# ET6801 register map
Vendor: ETMCU Inc.; File version: v0.0.1
CPU: CM7 r2p1, little endian, MPU, FPU, I-cache, D-cache, ITCM, DTCM, 4 interrupt priority bits
Registers are 32-bit, read-write, reset 0x0 unless marked. A register's access mark holds for its fields unless they carry their own. Offsets are from the block's base; [hi:lo] are bit positions; lines under a group give offsets from that group; {n}, {i} and the like mark numbered series.

## SDFM0 — Provide an overview of the purpose and functionality of the peripheral: sdfm_cfg
Base 0x40115000
Same registers: SDFM1 0x40116000, SDFM2 0x40117000, SDFM3 0x40118000
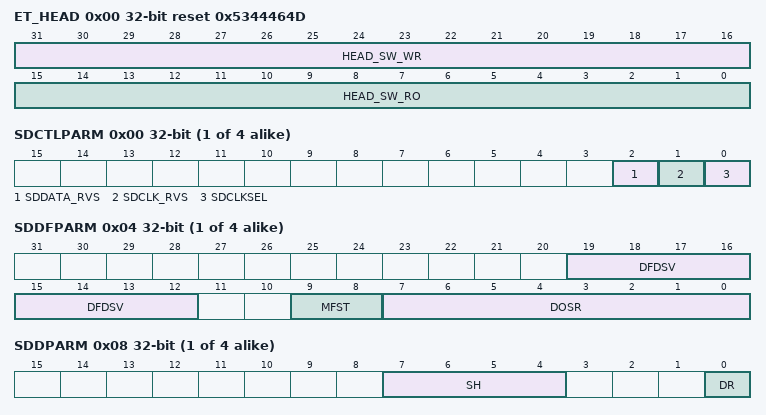
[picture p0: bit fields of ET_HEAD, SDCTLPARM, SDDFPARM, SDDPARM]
0x00 ET_HEAD reset 0x5344464D
  [31:16] HEAD_SW_WR — 软件测试读写寄存器，硬件无访问，静态寄存器
  [15:0] HEAD_SW_RO ro — 软件只读上报寄存器，硬件无访问,SDFM的ASICII 码表示，静态寄存器
{0x4+0x48*i} SDCHNX_GRP[{i}] (i=0..3) group
  0x00 SDCTLPARM
    [2] SDDATA_RVS — SD输入数据信号反向
    [1] SDCLK_RVS — SD输入时钟反向
    [0] SDCLKSEL — SD时钟源选择 对于通道1，当有多个SDFM模块挂到总线上时，是否选择其他SDFM模块通道1的滤波器时钟源为当前SDFM模块通道1的滤波器时钟源 'd0:通道1的滤波器的时钟源为自己通道的时钟； 'd1:通道1的滤波器的时钟源为其他SDFM模块的通道1的滤波器的时钟源 对于通道2~4 'd0:到SDFM滤波器的时钟源为自己通道的时钟源； 'd1:到SDFM滤波器的时钟源为当前SDFM模块通道1滤波器时钟源；
  0x04 SDDFPARM
    [19:12] DFDSV — 数据滤波器抽取计数器起始值(Data Filter Decimation count Start Value)，当开始或重新启动时，抽取计数器从值cfg_dfdsv开始计数。有效值为0~dosr。
    [9:8] MFST — 数据滤波器结构 'd0:数据过滤器以Sincfast结构运行; 'd1:数据过滤器以Sinc1结构运行; 'd2:数据过滤器以Sinc2结构运行; 'd3:数据过滤器以Sinc3结构运行;
    [7:0] DOSR — 数据滤波器过采样率 数据滤波器的实际过采样率为DOSR + 1。这些位设置了数据滤波器的过采样率。例如:0x0FF表示过采样率为256。
  0x08 SDDPARM
    [7:4] SH — 移位控制 这些位表示当选择16位数据表示时，16位窗口向上移动了多少位。
    [0] DR — 数据滤波器数据表示 'd0:以16位二进制补码存储数据； 'd1:以32位二进制补码存储数据；
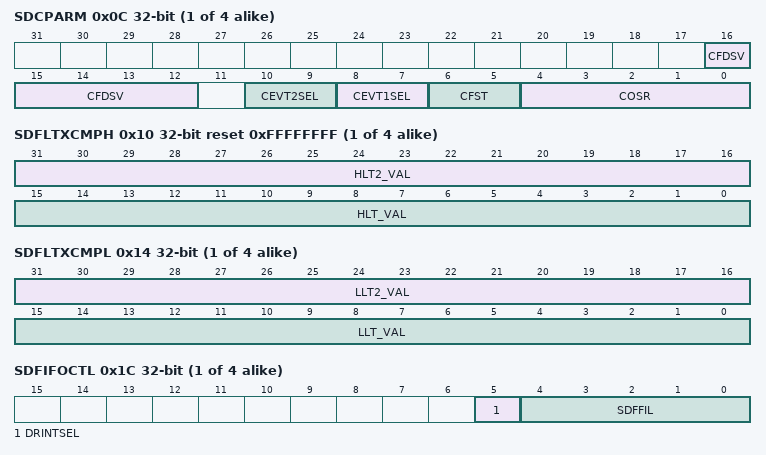
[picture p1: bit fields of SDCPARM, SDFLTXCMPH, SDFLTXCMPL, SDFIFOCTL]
  0x0C SDCPARM
    [16:12] CFDSV — 比较滤波器抽取计数器起始值(Comparator Filter Decimation count Start Value)，当开始或重新启动时，抽取计数器从值cfg_cfdsv开始计数。有效值为0~cosr。
    [10:9] CEVT2SEL — 比较器event2选择 'd0:compl1； 'd1: compl1或者comph1； 'd2:compl2； 'd3: compl2或者comph2；
    [8:7] CEVT1SEL — 比较器event1选择 'd0:comph1； 'd1: compl1或者comph1； 'd2:comph2； 'd3: compl2或者comph2；
    [6:5] CFST — 比较器滤波器结构 'd0:比较滤波器以sincfast结构运行 'd1:比较滤波器以Sinc1结构运行 'd2:比较滤波器以Sinc2结构运行 'd3:比较滤波器以Sinc3结构运行
    [4:0] COSR — 比较器过采样率 实际过采样率位COSR + 1，这些位设置了滤波器的过采样率。例如：0x1F表示过采样比为32
  0x10 SDFLTXCMPH reset 0xFFFFFFFF
    [31:16] HLT2_VAL — 比较滤波器输出的第二个无符号高阈值；
    [15:0] HLT_VAL — 比较滤波器输出的无符号高阈值。
  0x14 SDFLTXCMPL
    [31:16] LLT2_VAL — 比较滤波器输出的第二个无符号低阈值。
    [15:0] LLT_VAL — 比较滤波器输出的无符号低阈值。
  0x18 SDFLTXCMPHZ
    [15:0] HLTZ_VAL — 比较滤波器输出的无符号高阈值(Z)主要用于检测"零"交叉事件。与主比较器SDCMPHx不同，它不具有生成中断的能力。
  0x1C SDFIFOCTL
    [5] DRINTSEL — 数据就绪中断(DRINT)源选择 'd0: AFx(选择非fifo数据就绪中断) 'd1:SDFFINTx(选择FIFO数据就绪中断)
    [4:0] SDFFIL — SDFIFO中断门限 当FIFO状态(SDFFST) >= FIFO门限(SDFFIL)时，FIFO将产生中断。
  0x20 SDSYNC
    [5:0] SYNCSEL — 定义此通道上的SDSYNC输入源，0~35分别对应pwm输入信号的0~35输入源；其余选择为输入为0
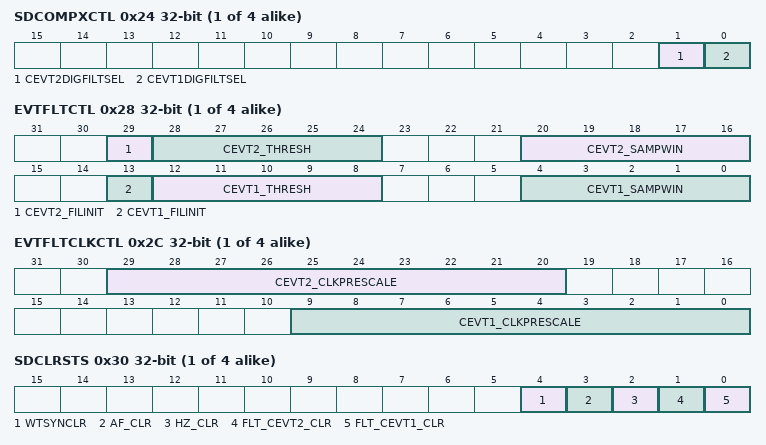
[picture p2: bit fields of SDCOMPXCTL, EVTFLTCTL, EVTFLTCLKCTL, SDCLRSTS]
  0x24 SDCOMPXCTL
    [1] CEVT2DIGFILTSEL — cevt2事件源选择。 'd0:CEVT2输出驱动器cevt2事件 'd1:数字滤波器输出驱动cevt2事件
    [0] CEVT1DIGFILTSEL — cevt1事件源选择。 'd0:CEVT1输出驱动器cevt1事件 'd1:数字滤波器输出驱动cevt1事件
  0x28 EVTFLTCTL
    [29] CEVT2_FILINIT wo — cevt2滤波器初始化。 'd0:无影响 'd1:将所有样本初始化为滤波器输入值
    [28:24] CEVT2_THRESH — cevt2滤波器多数投票阈值。为了使输出改变状态，必须在样本窗口内出现至少（THRESH+1）个相反状态的样本。
    [20:16] CEVT2_SAMPWIN — cevt2滤波器样本窗口大小。要监控的采样数为SAMPWIN+1。
    [13] CEVT1_FILINIT wo — cevt1滤波器初始化。 'd0:无影响 'd1:将所有样本初始化为滤波器输入值
    [12:8] CEVT1_THRESH — cevt1滤波器多数投票阈值。为了使输出改变状态，必须在样本窗口内出现至少（THRESH+1）个相反状态的样本。
    [4:0] CEVT1_SAMPWIN — cevt1滤波器样本窗口大小。要监控的采样数为SAMPWIN+1。
  0x2C EVTFLTCLKCTL
    [29:20] CEVT2_CLKPRESCALE — cevt2滤波器采样时钟预刻度。采样之间的系统时钟数。
    [9:0] CEVT1_CLKPRESCALE — cevt1滤波器采样时钟预刻度。采样之间的系统时钟数。
  0x30 SDCLRSTS
    [4] WTSYNCLR — 动态寄存器 Wait-for-Sync Flag Clear 'd0:写0不影响； 'd1:写1清空WTSYNFLG； 注：wtsynflg_rpt为fifo使用pwm同步功能时的fifo enable实时上报信号，如果用此处用硬件自清0，软件很有可能看不到wtsynflg_rpt清零的状态；
    [3] AF_CLR — 动态寄存器 主滤波器应答标志清除位
    [2] HZ_CLR — 动态寄存器 hz_rpt标志清除位
    [1] FLT_CEVT2_CLR — 动态寄存器 比较滤波器的CEVT2标志清除位
    [0] FLT_CEVT1_CLR — 动态寄存器 比较滤波器的CEVT1标志清除位
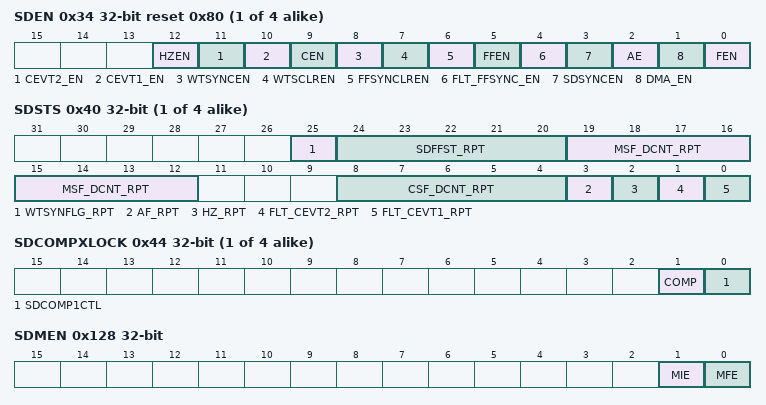
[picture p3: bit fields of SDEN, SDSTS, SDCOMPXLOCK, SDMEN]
  0x34 SDEN reset 0x80
    [12] HZEN — 动态寄存器 高电平(Z)使能阈值交叉输出 'd0:关闭高电平阈值(Z)交叉； 'd1:使能高电平阈值(Z)交叉；
    [11] CEVT2_EN — 动态寄存器 使能cevt2 'd0:关闭cevt2 'd1:使能cevt2
    [10] CEVT1_EN — 动态寄存器 使能cevt1 'd0:关闭cevt1 'd1:使能cevt1
    [9] CEN — 动态寄存器 比较滤波器使能 'd0:失能比较滤波器； 'd1:使能比较滤波器；
    [8] WTSYNCEN — 动态寄存器 Wait-for-Sync使能 'd0:每次DR (Data- ready)事件时，输入数据写入SDFIFO； 'd1:在发生SDSYNC事件后，DR事件的输入数据才会写入SDFIFO；
    [7] WTSCLREN — 动态寄存器 WTSYNFLG Clear-on-FIFOINT Enable 'd0: WTSYNFLG只能手动清除(使用WTSYNCLR位) 'd1:在SDFFINT有效时自动清除WTSYNFLG
    [6] FFSYNCLREN — 动态寄存器 FIFO Clear-on-SDSYNC Enable 'd0:表示SDFIFO接收到SDSYNC后不自动清除 'd1:SDFIFO接收到SDSYNC后自动清除
    [5] FFEN — 动态寄存器 SDFIFO启用 'd0:关闭FIFO操作 'd1:使能FIFO操作 注意:当失能FIFO时，FIFO内容将被清除
    [4] FLT_FFSYNC_EN — 动态寄存器 数据滤波器的enable和fifo的同步联动使能 'd0:数据滤波器的enable与FIFO的sync没有关系 'd1:数据滤波器的enable和fifo的同步联动
    [3] SDSYNCEN — 动态寄存器 数据滤波器的PWM同步(SDSYNC) 'd0:关闭数据滤波器PWM同步 'd1:开启数据滤波器PWM同步 注意:SDSYNCx.SYNCSEL位定义哪个PWM信号用于同步PWM
    [2] AE — 动态寄存器 数据滤波器应答使能 'd0:关闭特定滤波器的应答标志 'd1:使能特定滤波器的应答标志
    [1] DMA_EN — 动态寄存器 dma使能 'd0:失能dma; 'd1:使能dma;
    [0] FEN — 动态寄存器 滤波器使能 'd0:关闭数据滤波器，不产生数据； 'd1:启用数据滤波器，在数据滤波器中产生数据； 注意:当滤波器被失能时，DOSR计数器复位，滤波器数据被擦除。同时也重置FIFO指针并且清除FIFO。
  0x38 FIFO_DATA ro
    [31:0] FIFO_DATA — fifo读数据接口，这个寄存器的操作行为对应fifo的读数据行为，对内部的数据滤波器的结果寄存器进行读取操作
  0x3C SDCDATA ro
    [15:0] SDCDATA_RPT — 比较滤波器仅输出16位
  0x40 SDSTS ro
    [25] WTSYNFLG_RPT — Wait-for-Sync flag 'd0:未发生SDSYNC事件； 'd1:发生SDSYNC事件；
    [24:20] SDFFST_RPT — SDFIFO状态 'd0: FIFO空 'd1: FIFO有一个数 . . . . 'd16: FIFO有16个数
    [19:12] MSF_DCNT_RPT — 主sinc filter抽取计数器上报值
    [8:4] CSF_DCNT_RPT — 比较sinc filter抽取计数器上报值
    [3] AF_RPT — 滤波器应答标志,
    [2] HZ_RPT — 高电平阈值交叉(Z)标志 主要用于检测"过零"事件。与主比较器IFHx标志不同，它不具有产生中断的能力。 'd0:比较器滤波器输出< SDCMPHZx.HLTZ; 'd1:比较器滤波器输出>= SDCMPHZx.HLTZ;
    [1] FLT_CEVT2_RPT — CEVT2标志
    [0] FLT_CEVT1_RPT — CEVT1标志
  0x44 SDCOMPXLOCK
    [1] COMP — 动态寄存器 锁定对EVTFLTCTL和EVTFLTCLKCTL寄存器的写访问。 'd0:EVTFLTCTL和EVTFLTCLKCTL寄存器不锁定。 'd1:EVTFLTCTL和EVTFLTCLKCTL寄存器被锁定。
    [0] SDCOMP1CTL — 动态寄存器 锁定对SDCOMPXCTL寄存器的写访问。 'd0:SDCOMPXCTL寄存器未锁定。 'd1:SDCOMPXCTL寄存器被锁定。
0x124 SDMCLR
  [0] MIF_CLR — 动态寄存器 SDFM主中断标志的标志清除位。 'd0:对mif_rpt标志无影响; 'd1:清除mif_rpt标志; 注意:如果mif_rpt标志被清除，其他中断仍处于挂起状态，在接下来的SysClk周期中，mif_rpt将再次被设置为1,INT输出将被重新声明。
0x128 SDMEN
  [1] MIE — 动态寄存器 启用主SDy_ERR中断(包括除数据就绪中断之外的其他中断) 'd0:关闭SDy_ERR中断和中断标志 'd1:开启SDy_ERR中断和中断标志
  [0] MFE — 动态寄存器 主滤波器启用 'd0:关闭SDFM模块的4个数据过滤单元。所有fifo被清除; 'd1:如果位域cfg_fen为"1"，可以开启数据滤波器单元;
0x12C SDMSTS ro
  [0] MIF_RPT — 当任何"错误"中断(mf1-4,fltx_cevt1(x=1-4), fltx_cevt2(x=1-4),sdffovf1-4)处于活动状态时设置
0x130 INT_EN
  [27:0] INT_EN — 动态寄存器 bit27,bit20,bit13,bit6: 滤波器x数据准备中断(bit27,bit20,bit13,bit6分别对应x=4~1) 'd0:关闭数据准备中断; 'd1:使能数据准备中断; bit26,bit19,bit12,bit5: 滤波器x的fifo读数据错误中断(bit26,bit19,bit12,bit5分别对应x=4~1) 'd0:关闭fifo读数据错误中断; 'd1:使能fifo读数据错误中断; bit25,bit18,bit11,bit4: 滤波器x的fifo写数据错误中断(bit25,bit18,bit11,bit4分别对应x=4~1) 'd0:关闭fifo写数据错误中断; 'd1:使能fifo写数据错误中断; bit24,bit17,bit10,bit3: 滤波器x的fifo溢出标志中断(bit24,bit17,bit10,bit3分别对应x=4~1) 'd0:关闭fifo溢出标志中断; 'd1:使能fifo溢出标志中断; bit23,bit16,bit9,bit2: 滤波器x调制器故障中断(bit23,bit16,bit9,bit2分别对应x=4~1) 'd0:关闭调制器故障中断; 'd1:使能调制器故障中断; bit22,bit15,bit8,bit1: 滤波器x的cevt2中断(bit22,bit15,bit8,bit1分别对应x=4~1) 'd0:关闭cevt2中断; 'd1:使能cevt2中断; bit21,bit14,bit7,bit0: 滤波器x的cevt1中断(bit21,bit14,bit7,bit0分别对应x=4~1) 'd0:关闭cevt1中断; 'd1:使能cevt1中断;
0x134 INT_MASK
  [27:0] INT_MASK — 动态寄存器 中断屏蔽 'd0:取消屏蔽中断; 'd1:屏蔽中断;
0x138 INT_FORCE_IND
  [27:0] INT_FORCE_IND — 动态寄存器 1表示强制产生相应的测试中断，硬件自清零
0x13C INT_CLR
  [27:0] INT_CLR — 动态寄存器 1表示清除相应的中断状态，硬件自清零
0x140 INT_RAW_RPT ro
  [27:0] INT_RAW_RPT — 动态寄存器，中断MASK前RAW 中断状态上报
0x144 INT_STATUS_RPT ro
  [27:0] INT_STATUS_RPT — 动态寄存器，中断MASK后中断状态上报
0x148 DEBUGP
  [3:0] DBP_SEL — 动态寄存器 debug ports选择档位，此版本未使用 'd0:通道1的 ;
0x14C MULSDCIN
  [0] SEL — 当MCU包含四个SDFM时，SDFM0/1/2/3 若cfg_sdclksel为1'b1,SDFM3可以配置该字段选择： 1'b0:sdfm0_c0作为SDFM4的时钟源 1'b1:sdfm2_c0作为SDFM4的时钟源
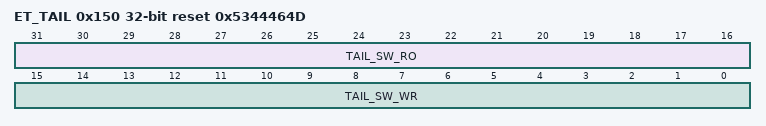
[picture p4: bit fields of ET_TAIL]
0x150 ET_TAIL reset 0x5344464D
  [31:16] TAIL_SW_RO ro — 软件只读硬件上报寄存器，静态寄存器
  [15:0] TAIL_SW_WR — 软件测试读写寄存器，硬件无访问，静态寄存器
